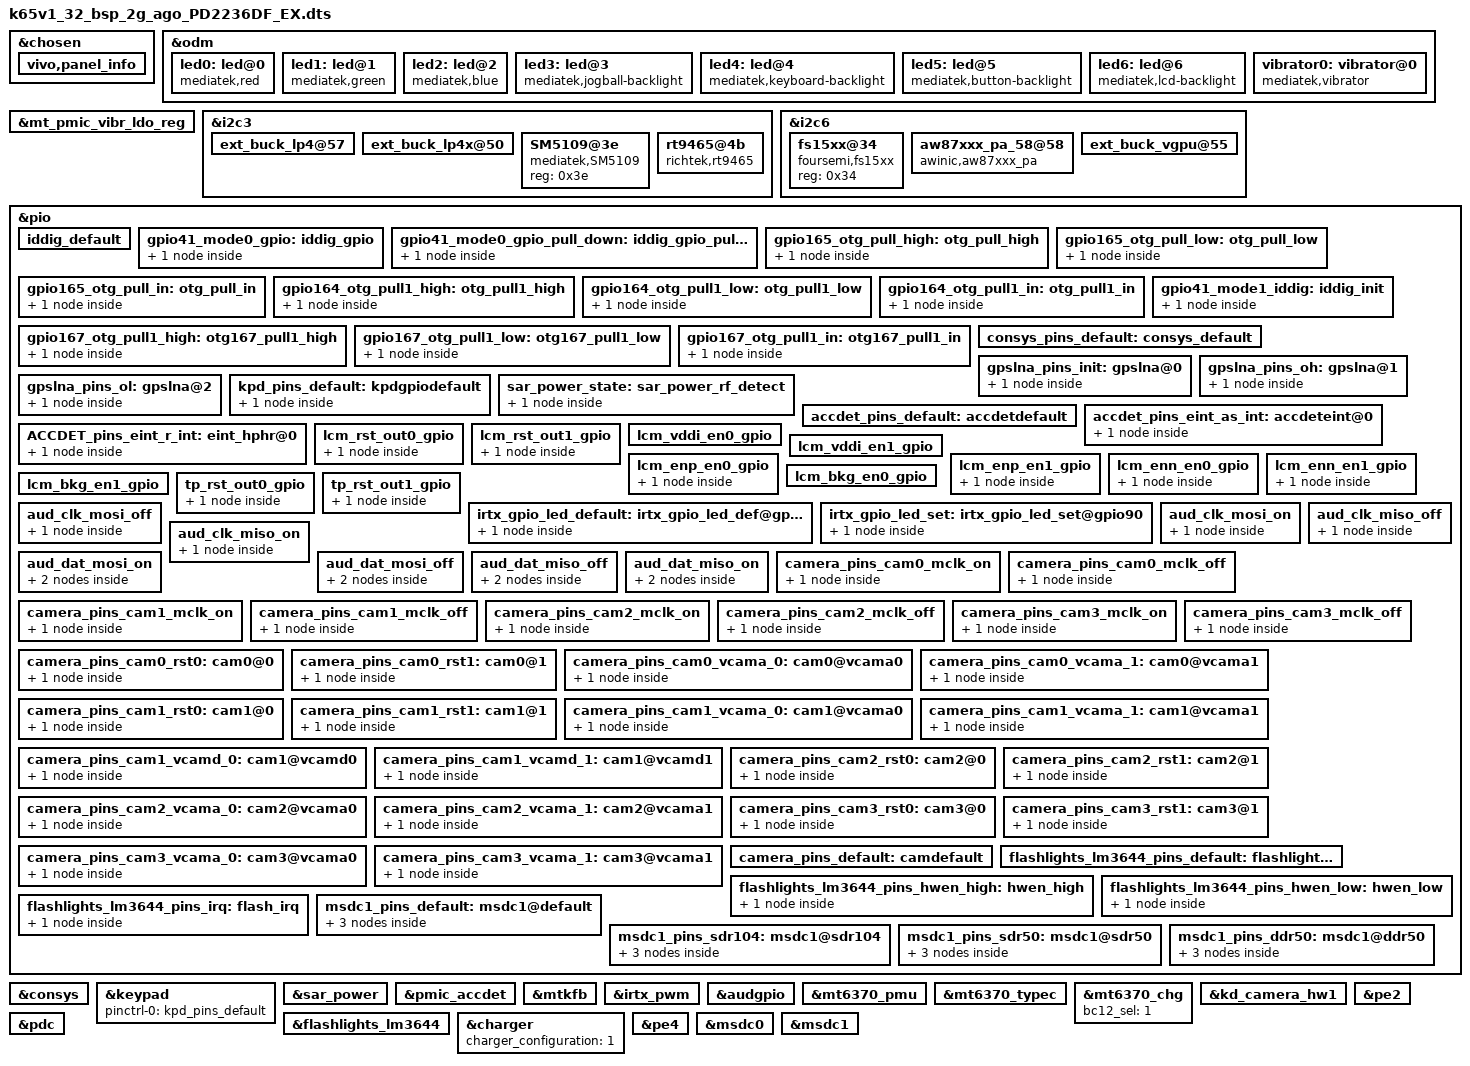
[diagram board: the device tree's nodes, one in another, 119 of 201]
// SPDX-License-Identifier: GPL-2.0+
/*
 * Copyright (c) 2019 MediaTek Inc.
 *
 */

#include <dt-bindings/interrupt-controller/arm-gic.h>
#include <dt-bindings/interrupt-controller/irq.h>
#include <dt-bindings/pinctrl/mt6765-pinfunc.h>
#include <dt-bindings/clock/mt6765-clk.h>
#include <dt-bindings/mmc/mt6765-msdc.h>

/dts-v1/;
/plugin/;

/* chosen */
&chosen {

	/* fpga may has no lk, we need to specify display info here */
	/* fb buffer is reserved using this dts by memory node above */
	atag,videolfb-fb_base_h = <0x0>;
	atag,videolfb-fb_base_l = <0x5e605000>;
	atag,videolfb-islcmfound = <1>;
	/* because no lk, so lcm is not inited */
	atag,videolfb-islcm_inited = <0>;
	atag,videolfb-fps= <6000>;
	atag,videolfb-vramSize= <0x017bb000>;
	atag,videolfb-lcmname= "pd2236_txd_jd9365t_hdplus_dsi_vdo";
	atag,videolfb-project-name= "PD2236DF_EX";
	/* vivo panel materiel info start */
	vivo,panel_info {
		/*
		 * No add new id until you have import driver for new panel ok!!!!!!
		 * vivo,panel-materiel-id-list = "materiel_id1", "lcm1_sf_id1 lcm1_sf_id2 lcm1_sf_id3...",
		 *				 "materiel_id2", "lcm2_sf_id1 lcm2_sf_id2 lcm2_sf_id3...",
		 *				 ...
		 *				 "materiel_idX", "lcmX_sf_id1 lcmX_sf_id2 lcmX_sf_id3...";
		 */

		vivo,panel-materiel-id-list = "1111111","0x90",		/*txd_jd9365t*/
									  "2222222","0xB1",		/*ski651_icnl9911c*/
									  "3333333","0x12";     /*tianma_ili9883c*/
	};

	/* vivo panel materiel info end */
};

&odm {
	led0:led@0 {
		compatible = "mediatek,red";
		led_mode = <0>;
		data = <1>;
		pwm_config = <0 0 0 0 0>;
	};
	led1:led@1 {
		compatible = "mediatek,green";
		led_mode = <0>;
		data = <1>;
		pwm_config = <0 0 0 0 0>;
	};
	led2:led@2 {
		compatible = "mediatek,blue";
		led_mode = <0>;
		data = <1>;
		pwm_config = <0 0 0 0 0>;
	};
	led3:led@3 {
		compatible = "mediatek,jogball-backlight";
		led_mode = <0>;
		data = <1>;
		pwm_config = <0 0 0 0 0>;
	};
	led4:led@4 {
		compatible = "mediatek,keyboard-backlight";
		led_mode = <0>;
		data = <1>;
		pwm_config = <0 0 0 0 0>;
	};
	led5:led@5 {
		compatible = "mediatek,button-backlight";
		led_mode = <0>;
		data = <1>;
		pwm_config = <0 0 0 0 0>;
	};
	led6:led@6 {
		compatible = "mediatek,lcd-backlight";
		led_mode = <4>;
		data = <1>;
		pwm_config = <0 0 0 0 0>;
	};
	vibrator0:vibrator@0 {
		compatible = "mediatek,vibrator";
		vib_timer = <25>;
		vib_limit = <9>;
		vib_vol= <9>;
	};
};

&mt_pmic_vibr_ldo_reg {
	regulator-min-microvolt = <3000000>;
	regulator-max-microvolt = <3000000>;
};

&i2c3 {
	ext_buck_lp4@57 {
		regulator-name ="ext_buck_vdd2";
		regulator-min-microvolt = <300000>;
		regulator-max-microvolt = <1300000>;
		vsel_pin = <0>;
	};

	ext_buck_lp4x@50 {
		regulator-name ="ext_buck_vddq";
		regulator-min-microvolt = <300000>;
		regulator-max-microvolt = <1300000>;
		vsel_pin = <1>;
	};

	SM5109@3e {
		compatible = "mediatek,SM5109";
		reg = <0x3e>;
		status = "okay";
	};
};

&i2c6 {
	/* AWINIC FS1599 Smart K PA */
	fs15xx@34 {
		compatible = "foursemi,fs15xx";
		reg = <0x34>;
		status = "okay";
	};
	/* AWINIC FS1599 Smart K PA End */

	/* AWINIC AW87XXX Smart K PA */
	aw87xxx_pa_58@58 {
		compatible = "awinic,aw87xxx_pa";
		reg = <0x58>;
		//reset-gpio = <&pio 173 0>;
		dev_index = < 0 >;
		status = "okay";
	};
	/* AWINIC AW87XXX Smart K PA End */

	ext_buck_vgpu@55 {
		regulator-name ="ext_buck_vgpu";
		regulator-min-microvolt = <300000>;
		regulator-max-microvolt = <1300000>;
		vsel_pin = <2>;
	};
};

/*HQ charge add otg start*/
&pio {
	iddig_default: iddig_default {
	};

	gpio41_mode0_gpio: iddig_gpio {
		pins_cmd_dat {
			pinmux = <PINMUX_GPIO41__FUNC_GPIO41>;
			input-enable;
			slew-rate = <0>;
			bias-pull-up = <01>;
			bias-disable;
		};
	};

	gpio41_mode0_gpio_pull_down: iddig_gpio_pull_down {
		pins_cmd_dat {
			pinmux = <PINMUX_GPIO41__FUNC_GPIO41>;
			input-enable;
			slew-rate = <0>;
			/*bias-pull-up = <00>;*/
			bias-pull-down;
		};
	};

	gpio165_otg_pull_high: otg_pull_high {
		pins_cmd_dat {
			pinmux = <PINMUX_GPIO110__FUNC_GPIO110>;
			slew-rate = <1>;
			bias-pull-up = <1>;
			output-high;
		};
	};
	gpio165_otg_pull_low: otg_pull_low {
		pins_cmd_dat {
			pinmux = <PINMUX_GPIO110__FUNC_GPIO110>;
			slew-rate = <1>;
			output-low;
		};
	};
	gpio165_otg_pull_in: otg_pull_in {
		pins_cmd_dat {
			pinmux = <PINMUX_GPIO110__FUNC_GPIO110>;
			input-enable;
			slew-rate = <0>;
			/*bias-pull-up = <00>;*/
			bias-disable;
		};
	};

	gpio164_otg_pull1_high: otg_pull1_high {
		pins_cmd_dat {
			pinmux = <PINMUX_GPIO164__FUNC_GPIO164>;
			slew-rate = <1>;
			bias-pull-up = <1>;
			output-high;
		};
	};
	gpio164_otg_pull1_low: otg_pull1_low {
		pins_cmd_dat {
			pinmux = <PINMUX_GPIO164__FUNC_GPIO164>;
			slew-rate = <1>;
			output-low;
		};
	};
	gpio164_otg_pull1_in: otg_pull1_in {
		pins_cmd_dat {
			pinmux = <PINMUX_GPIO164__FUNC_GPIO164>;
			input-enable;
			slew-rate = <0>;
			/*bias-pull-up = <00>;*/
			bias-disable;
		};
	};

	gpio41_mode1_iddig: iddig_init {
		pins_cmd_dat {
			pinmux = <PINMUX_GPIO41__FUNC_IDDIG>;
			input-enable;
			slew-rate = <0>;
			bias-pull-up = <01>;
			bias-disable;
		};
	};

	gpio167_otg_pull1_high: otg167_pull1_high {
		pins_cmd_dat {
			pinmux = <PINMUX_GPIO167__FUNC_GPIO167>;
			slew-rate = <1>;
			bias-pull-up = <1>;
			output-high;
		};
	};
	gpio167_otg_pull1_low: otg167_pull1_low {
		pins_cmd_dat {
			pinmux = <PINMUX_GPIO167__FUNC_GPIO167>;
			slew-rate = <1>;
			output-low;
		};
	};
	gpio167_otg_pull1_in: otg167_pull1_in {
		pins_cmd_dat {
			pinmux = <PINMUX_GPIO167__FUNC_GPIO167>;
			input-enable;
			slew-rate = <0>;
			/*bias-pull-up = <00>;*/
			bias-disable;
		};
	};
};
/*HQ charge add otg end*/

/* CONSYS GPIO standardization */
&pio {
	consys_pins_default: consys_default {
	};
	gpslna_pins_init: gpslna@0 {
		pins_cmd_dat {
			pinmux = <PINMUX_GPIO91__FUNC_GPIO91>;
			slew-rate = <0>;
			bias-disable;
			output-low;
		};
	};
	gpslna_pins_oh: gpslna@1 {
		pins_cmd_dat {
			pinmux = <PINMUX_GPIO91__FUNC_GPIO91>;
			slew-rate = <1>;
			output-high;
		};
	};
	gpslna_pins_ol: gpslna@2 {
		pins_cmd_dat {
			pinmux = <PINMUX_GPIO91__FUNC_GPIO91>;
			slew-rate = <1>;
			output-low;
		};
	};
};
&consys {
	pinctrl-names = "default", "gps_lna_state_init",
		"gps_lna_state_oh", "gps_lna_state_ol";
	pinctrl-0 = <&consys_pins_default>;
	pinctrl-1 = <&gpslna_pins_init>;
	pinctrl-2 = <&gpslna_pins_oh>;
	pinctrl-3 = <&gpslna_pins_ol>;
	status = "okay";
};
/* CONSYS end */

&keypad {
	pinctrl-names = "default";
	pinctrl-0 = <&kpd_pins_default>;
};

&pio {
	kpd_pins_default: kpdgpiodefault {
		pins_cmd_dat {
			pinmux = <PINMUX_GPIO93__FUNC_KPCOL0>;
			bias-pull-up = <MTK_PUPD_SET_R1R0_10>;
			output-low;
			input-schmitt-enable;
		};
	};
};

/* ADD by vsensor team for SAR Power */
&pio {
	sar_power_state: sar_power_rf_detect {
		pins_cmd0_dat {
			pinmux = <PINMUX_GPIO54__FUNC_GPIO54>;
			slew-rate = <0>;
			bias-disable;
		};
	};
};

&sar_power {
	status="okay";
	pinctrl-names = "default";
	pinctrl-0 = <&sar_power_state>;
	sar-power-rf-detect,gpios= <&pio 54 0x0>;
};
/* ADD by vsensor team for SAR Power */

/* accdet start */
&pmic_accdet {
	accdet-mic-vol = <6>;
	headset-mode-setting = <0x500 0x500 1 0x1f0 0x800 0x800 0x2000 0x44>;
	accdet-plugout-debounce = <16>;
	accdet-mic-mode = <1>;
	headset-eint-level-pol = <8>;
	headset-three-key-threshold = <0 80 190 390>;
	headset-three-key-threshold-CDD = <0 121 192 600>;
	headset-four-key-threshold = <0 53 90 190 390>;
	pinctrl-names = "default", "state_eint_as_int","state_eint_r_as_int";
	pinctrl-0 = <&accdet_pins_default>;
	pinctrl-1 = <&accdet_pins_eint_as_int>;
	pinctrl-2 = <&ACCDET_pins_eint_r_int>;
	status = "okay";
};
&pio {
	accdet_pins_default: accdetdefault {
	};
	accdet_pins_eint_as_int: accdeteint@0 {
		pins_cmd_dat {
			pinmux = <PINMUX_GPIO4__FUNC_GPIO4>;
			slew-rate = <0>;
			bias-disable;
		};
	};
	ACCDET_pins_eint_r_int:eint_hphr@0{
			pins_cmd_dat {
				pinmux = <PINMUX_GPIO3__FUNC_GPIO3>;
				slew-rate = <0>;
				bias-disable;
			};
	};
};
/* accdet end */

/* FINGERPRINT start */
/*&spi0 {
	#address-cells = <1>;
	#size-cells = <0>;
	fingerprint@0 {
		compatible = "goodix,goodix-fp";
		reg = <0>;
		spi-max-frequency = <8000000>;
		netlink-event = <30>;
		status = "okay";
	};
};*/

/*&goodix_fp {
	pinctrl-names = "default", "reset_high", "reset_low";
	pinctrl-0 = <&fingerprint_default>;
	pinctrl-1 = <&fingerprint_reset_high>;
	pinctrl-2 = <&fingerprint_reset_low>;
	status = "okay";
};*/

/*&pio {
	fingerprint_default: state_default {
	};
	fingerprint_reset_high: state_reset_high {
		pins_cmd_dat {
			pinmux = <PINMUX_GPIO172__FUNC_GPIO172>;
			slew-rate = <1>;
			output-high;
		};
	};
	fingerprint_reset_low: state_reset_low {
		pins_cmd_dat {
			pinmux = <PINMUX_GPIO172__FUNC_GPIO172>;
			slew-rate = <1>;
			output-low;
		};
	};
};*/
/* FINGERPRINT end */


&i2c6 {
	#address-cells = <1>;
	#size-cells = <0>;
	clock-frequency = <400000>;
	mediatek,use-open-drain;
	/*lm3697_i2c@36 {
		compatible = "lm3697_i2c";
		reg = <0x36>;
		status = "okay";
	};*/
};

/* add for lcm gpio config start  */
&mtkfb {
	pinctrl-names = "lcm_rst_out0_gpio",
					"lcm_rst_out1_gpio",
					"lcm_vddi_en0_gpio",
					"lcm_vddi_en1_gpio",
					"lcm_enp_en0_gpio",
					"lcm_enp_en1_gpio",
					"lcm_enn_en0_gpio",
					"lcm_enn_en1_gpio",
					"lcm_bkg_en0_gpio",
					"lcm_bkg_en1_gpio",
					"tp_rst_out0_gpio",
					"tp_rst_out1_gpio";

	pinctrl-0 = <&lcm_rst_out0_gpio>;
	pinctrl-1 = <&lcm_rst_out1_gpio>;

	pinctrl-2 = <&lcm_vddi_en0_gpio>;
	pinctrl-3 = <&lcm_vddi_en1_gpio>;

	pinctrl-4 = <&lcm_enp_en0_gpio>;
	pinctrl-5 = <&lcm_enp_en1_gpio>;

	pinctrl-6 = <&lcm_enn_en0_gpio>;
	pinctrl-7 = <&lcm_enn_en1_gpio>;

	pinctrl-8 = <&lcm_bkg_en0_gpio>;
	pinctrl-9 = <&lcm_bkg_en1_gpio>;

	pinctrl-10 = <&tp_rst_out0_gpio>;
	pinctrl-11 = <&tp_rst_out1_gpio>;

	status = "okay";
};
&pio {
	lcm_rst_out0_gpio: lcm_rst_out0_gpio {
		pins_cmd_dat {
			pinmux = <PINMUX_GPIO45__FUNC_GPIO45>;
			slew-rate = <1>;
			output-low;
		};
	};
	lcm_rst_out1_gpio: lcm_rst_out1_gpio {
		pins_cmd_dat {
			pinmux = <PINMUX_GPIO45__FUNC_GPIO45>;
			slew-rate = <1>;
			output-high;
		};
	};
	lcm_vddi_en0_gpio: lcm_vddi_en0_gpio {
	};
	lcm_vddi_en1_gpio: lcm_vddi_en1_gpio {
	};

	lcm_enp_en0_gpio: lcm_enp_en0_gpio {
		pins_cmd_dat {
			pinmux = <PINMUX_GPIO166__FUNC_GPIO166>;
			slew-rate = <1>;
			output-low;
		};
	};
	lcm_enp_en1_gpio: lcm_enp_en1_gpio {
		pins_cmd_dat {
			pinmux = <PINMUX_GPIO166__FUNC_GPIO166>;
			slew-rate = <1>;
			output-high;
		};
	};

	lcm_enn_en0_gpio: lcm_enn_en0_gpio {
		pins_cmd_dat {
			pinmux = <PINMUX_GPIO165__FUNC_GPIO165>;
			slew-rate = <1>;
			output-low;
		};
	};
	lcm_enn_en1_gpio: lcm_enn_en1_gpio {
		pins_cmd_dat {
			pinmux = <PINMUX_GPIO165__FUNC_GPIO165>;
			slew-rate = <1>;
			output-high;
		};
	};

	lcm_bkg_en0_gpio: lcm_bkg_en0_gpio {
	};
	lcm_bkg_en1_gpio: lcm_bkg_en1_gpio {
	};

	tp_rst_out0_gpio: tp_rst_out0_gpio {
		pins_cmd_dat {
			pinmux = <PINMUX_GPIO178__FUNC_GPIO178>;
			slew-rate = <1>;
			output-low;
		};
	};
	tp_rst_out1_gpio: tp_rst_out1_gpio {
		pins_cmd_dat {
			pinmux = <PINMUX_GPIO178__FUNC_GPIO178>;
			slew-rate = <1>;
			output-high;
		};
	};
};
/* add for lcm gpio config end  */

/* IRTX GPIO start */
&irtx_pwm {
	pinctrl-names = "irtx_gpio_led_default", "irtx_gpio_led_set";
	pinctrl-0 = <&irtx_gpio_led_default>;
	pinctrl-1 = <&irtx_gpio_led_set>;
	status = "okay";
};
&pio {
	irtx_gpio_led_default:irtx_gpio_led_def@gpio90 {
		pins_cmd_dat {
			pinmux = <PINMUX_GPIO90__FUNC_GPIO90>;
			slew-rate = <1>;
			bias-disable;
			output-low;
			input-schmitt-enable = <0>;
		};
	};

	irtx_gpio_led_set:irtx_gpio_led_set@gpio90 {
		pins_cmd_dat {
			pinmux = <PINMUX_GPIO90__FUNC_PWM0>;
			slew-rate = <1>;
			output-high;
		};
	};
};
/* IRTX GPIO Settings -End */

/* AUDIO GPIO standardization */
&audgpio {
	pinctrl-names = "aud_clk_mosi_off",
			"aud_clk_mosi_on",
			"aud_clk_miso_off",
			"aud_clk_miso_on",
			"aud_dat_mosi_off",
			"aud_dat_mosi_on",
			"aud_dat_miso_off",
			"aud_dat_miso_on",
			"aud_smartpa_off",
			"aud_smartpa_on";
	pinctrl-0 = <&aud_clk_mosi_off>;
	pinctrl-1 = <&aud_clk_mosi_on>;
	pinctrl-2 = <&aud_clk_miso_off>;
	pinctrl-3 = <&aud_clk_miso_on>;
	pinctrl-4 = <&aud_dat_mosi_off>;
	pinctrl-5 = <&aud_dat_mosi_on>;
	pinctrl-6 = <&aud_dat_miso_off>;
	pinctrl-7 = <&aud_dat_miso_on>;
	//pinctrl-8 = <&aud_pins_smartpa_off>;
	//pinctrl-9 = <&aud_pins_smartpa_on>;
	status = "okay";
};

&pio {
	aud_clk_mosi_off: aud_clk_mosi_off {
		pins_cmd0_dat {
			pinmux = <PINMUX_GPIO136__FUNC_GPIO136>;
		};
	};

	aud_clk_mosi_on: aud_clk_mosi_on {
		pins_cmd0_dat {
			pinmux = <PINMUX_GPIO136__FUNC_AUD_CLK_MOSI>;
		};
	};

	aud_clk_miso_off: aud_clk_miso_off {
		pins_cmd0_dat {
			pinmux = <PINMUX_GPIO140__FUNC_GPIO140>;
		};
	};

	aud_clk_miso_on: aud_clk_miso_on {
		pins_cmd0_dat {
			pinmux = <PINMUX_GPIO140__FUNC_AUD_CLK_MISO>;
		};
	};

	aud_dat_mosi_off: aud_dat_mosi_off {
		pins_cmd1_dat {
			pinmux = <PINMUX_GPIO138__FUNC_GPIO138>;
			input-enable;
			slew-rate = <0>;
			bias-disable;
		};
		pins_cmd2_dat {
			pinmux = <PINMUX_GPIO139__FUNC_GPIO139>;
			input-enable;
			slew-rate = <0>;
			bias-disable;
		};
	};

	aud_dat_mosi_on: aud_dat_mosi_on {
		pins_cmd1_dat {
			pinmux = <PINMUX_GPIO138__FUNC_AUD_DAT_MOSI0>;
		};
		pins_cmd2_dat {
			pinmux = <PINMUX_GPIO139__FUNC_AUD_DAT_MOSI1>;
		};
	};

	aud_dat_miso_off: aud_dat_miso_off {
		pins_cmd1_dat {
			pinmux = <PINMUX_GPIO142__FUNC_GPIO142>;
			input-enable;
			slew-rate = <0>;
			bias-disable;
		};
		pins_cmd2_dat {
			pinmux = <PINMUX_GPIO143__FUNC_GPIO143>;
			input-enable;
			slew-rate = <0>;
			bias-disable;
		};
	};

	aud_dat_miso_on: aud_dat_miso_on {
		pins_cmd1_dat {
			pinmux = <PINMUX_GPIO142__FUNC_AUD_DAT_MISO0>;
		};
		pins_cmd2_dat {
			pinmux = <PINMUX_GPIO143__FUNC_AUD_DAT_MISO1>;
		};
	};
/*
	aud_pins_smartpa_off: aud_pins_smartpa_off {
		pins_cmd0_dat {
			pinmux = <PINMUX_GPIO17__FUNC_GPIO17>;
		};
		pins_cmd1_dat {
			pinmux = <PINMUX_GPIO18__FUNC_GPIO18>;
		};
		pins_cmd2_dat {
			pinmux = <PINMUX_GPIO19__FUNC_GPIO19>;
		};
		pins_cmd3_dat {
			pinmux = <PINMUX_GPIO20__FUNC_GPIO20>;
		};
	};

	aud_pins_smartpa_on: aud_pins_smartpa_on {
		pins_cmd0_dat {
			pinmux = <PINMUX_GPIO17__FUNC_I2S0_DI>;
		};
		pins_cmd1_dat {
			pinmux = <PINMUX_GPIO18__FUNC_I2S3_BCK>;
		};
		pins_cmd2_dat {
			pinmux = <PINMUX_GPIO19__FUNC_I2S3_LRCK>;
		};
		pins_cmd3_dat {
			pinmux = <PINMUX_GPIO20__FUNC_I2S3_DO>;
		};
	};
*/
};
/* AUDIO end */

&mt6370_pmu {
	mt6370,intr_gpio_num = <11>; /* direct defined GPIO num */
	mt6370,intr_gpio = <&pio 11 0x0>;
};

&mt6370_typec {
	mt6370pd,intr_gpio_num = <41>; /* direct defined GPIO num */
	mt6370pd,intr_gpio = <&pio 41 0x0>;
};

&mt6370_chg {
	bc12_sel = <1>;
};

&pio {
	camera_pins_cam0_mclk_on: camera_pins_cam0_mclk_on {
		pins_cmd_dat {
			pinmux = <PINMUX_GPIO99__FUNC_CMMCLK0>;
		};
	};
	camera_pins_cam0_mclk_off: camera_pins_cam0_mclk_off {
		pins_cmd_dat {
			pinmux = <PINMUX_GPIO99__FUNC_GPIO99>;
		};
	};
	camera_pins_cam1_mclk_on: camera_pins_cam1_mclk_on {
		pins_cmd_dat {
			pinmux = <PINMUX_GPIO100__FUNC_CMMCLK1>;
		};
	};
	camera_pins_cam1_mclk_off: camera_pins_cam1_mclk_off {
		pins_cmd_dat {
			pinmux = <PINMUX_GPIO100__FUNC_GPIO100>;
		};
	};
	camera_pins_cam2_mclk_on: camera_pins_cam2_mclk_on {
		pins_cmd_dat {
			pinmux = <PINMUX_GPIO108__FUNC_CMMCLK2>;
		};
	};
	camera_pins_cam2_mclk_off: camera_pins_cam2_mclk_off {
		pins_cmd_dat {
			pinmux = <PINMUX_GPIO108__FUNC_GPIO108>;
		};
	};
	camera_pins_cam3_mclk_on: camera_pins_cam3_mclk_on {
		pins_cmd_dat {
			pinmux = <PINMUX_GPIO100__FUNC_CMMCLK1>;
		};
	};
	camera_pins_cam3_mclk_off: camera_pins_cam3_mclk_off {
		pins_cmd_dat {
			pinmux = <PINMUX_GPIO100__FUNC_GPIO100>;
		};
	};
/* cam 0 main start*/
	camera_pins_cam0_rst0: cam0@0 {
		pins_cmd_dat {
			pinmux = <PINMUX_GPIO101__FUNC_GPIO101>;
			slew-rate = <1>;
			output-low;
		};
	};
	camera_pins_cam0_rst1: cam0@1 {
		pins_cmd_dat {
			pinmux = <PINMUX_GPIO101__FUNC_GPIO101>;
			slew-rate = <1>;
			output-high;
		};
	};

	camera_pins_cam0_vcama_0: cam0@vcama0 {
		pins_cmd_dat {
			pinmux = <PINMUX_GPIO156__FUNC_GPIO156>;
			slew-rate = <1>;
			output-low;
		};
	};
	camera_pins_cam0_vcama_1: cam0@vcama1 {
		pins_cmd_dat {
			pinmux = <PINMUX_GPIO156__FUNC_GPIO156>;
			slew-rate = <1>;
			output-high;
		};
	};
/* cam 0 main end*/

/* cam 1 sub start*/

	camera_pins_cam1_rst0: cam1@0 {
		pins_cmd_dat {
			pinmux = <PINMUX_GPIO102__FUNC_GPIO102>;
			slew-rate = <1>;
			output-low;
		};
	};
	camera_pins_cam1_rst1: cam1@1 {
		pins_cmd_dat {
			pinmux = <PINMUX_GPIO102__FUNC_GPIO102>;
			slew-rate = <1>;
			output-high;
		};
	};
	camera_pins_cam1_vcama_0: cam1@vcama0 {
		pins_cmd_dat {
			pinmux = <PINMUX_GPIO156__FUNC_GPIO156>;
			slew-rate = <1>;
			output-low;
		};
	};
	camera_pins_cam1_vcama_1: cam1@vcama1 {
		pins_cmd_dat {
			pinmux = <PINMUX_GPIO156__FUNC_GPIO156>;
			slew-rate = <1>;
			output-high;
		};
	};
	camera_pins_cam1_vcamd_0: cam1@vcamd0 {
		pins_cmd_dat {
			pinmux = <PINMUX_GPIO98__FUNC_GPIO98>;
			slew-rate = <1>;
			output-low;
		};
	};
	camera_pins_cam1_vcamd_1: cam1@vcamd1 {
		pins_cmd_dat {
			pinmux = <PINMUX_GPIO98__FUNC_GPIO98>;
			slew-rate = <1>;
			output-high;
		};
	};

/* cam 1 sub end*/

/* cam 2 main2 start*/

	camera_pins_cam2_rst0: cam2@0 {
		pins_cmd_dat {
			pinmux = <PINMUX_GPIO109__FUNC_GPIO109>;
			slew-rate = <1>;
			output-low;
		};
	};
	camera_pins_cam2_rst1: cam2@1 {
		pins_cmd_dat {
			pinmux = <PINMUX_GPIO109__FUNC_GPIO109>;
			slew-rate = <1>;
			output-high;
		};

	};
	camera_pins_cam2_vcama_0: cam2@vcama0 {
		pins_cmd_dat {
			pinmux = <PINMUX_GPIO156__FUNC_GPIO156>;
			slew-rate = <1>;
			output-low;
		};
	};
	camera_pins_cam2_vcama_1: cam2@vcama1 {
		pins_cmd_dat {
			pinmux = <PINMUX_GPIO156__FUNC_GPIO156>;
			slew-rate = <1>;
			output-high;
		};
	};

/* cam 2 main2 end*/

/* cam 3 main3 start*/

	camera_pins_cam3_rst0: cam3@0 {
		pins_cmd_dat {
			pinmux = <PINMUX_GPIO102__FUNC_GPIO102>;
			slew-rate = <1>;
			output-low;
		};
	};
	camera_pins_cam3_rst1: cam3@1 {
		pins_cmd_dat {
			pinmux = <PINMUX_GPIO102__FUNC_GPIO102>;
			slew-rate = <1>;
			output-high;
		};

	};
	camera_pins_cam3_vcama_0: cam3@vcama0 {
		pins_cmd_dat {
			pinmux = <PINMUX_GPIO97__FUNC_GPIO97>;
			slew-rate = <1>;
			output-low;
		};
	};
	camera_pins_cam3_vcama_1: cam3@vcama1 {
		pins_cmd_dat {
			pinmux = <PINMUX_GPIO97__FUNC_GPIO97>;
			slew-rate = <1>;
			output-high;
		};
	};

/* cam 3 main3 end*/

	camera_pins_default: camdefault {
	};

};

&kd_camera_hw1 {
	pinctrl-names = "default",
			"cam0_rst0",
			"cam0_rst1",
			"cam1_rst0",
			"cam1_rst1",
			//"cam2_rst0",
			//"cam2_rst1",
			//"cam3_rst0",
			//"cam3_rst1",
			"cam0_ldo_vcama_0","cam0_ldo_vcama_1",
			//"cam1_ldo_vcamd_0","cam1_ldo_vcamd_1",
			"cam1_ldo_vcama_0","cam1_ldo_vcama_1",
			//"cam2_ldo_vcama_0","cam2_ldo_vcama_1",
			//"cam3_ldo_vcama_0","cam3_ldo_vcama_1",
			"cam0_mclk_on",
			"cam0_mclk_off",
			"cam1_mclk_on",
			"cam1_mclk_off";
			//"cam2_mclk_on",
			//"cam2_mclk_off",
			//"cam3_mclk_on",
			//"cam3_mclk_off";
	pinctrl-0 = <&camera_pins_default>;
	pinctrl-1 = <&camera_pins_cam0_rst0>;
	pinctrl-2 = <&camera_pins_cam0_rst1>;
	pinctrl-3 = <&camera_pins_cam1_rst0>;
	pinctrl-4 = <&camera_pins_cam1_rst1>;
	pinctrl-5 = <&camera_pins_cam0_vcama_0>;
	pinctrl-6 = <&camera_pins_cam0_vcama_1>;
	pinctrl-7 = <&camera_pins_cam1_vcama_0>;
	pinctrl-8 = <&camera_pins_cam1_vcama_1>;
	pinctrl-9 = <&camera_pins_cam0_mclk_on>;
	pinctrl-10 = <&camera_pins_cam0_mclk_off>;
	pinctrl-11 = <&camera_pins_cam1_mclk_on>;
	pinctrl-12 = <&camera_pins_cam1_mclk_off>;

	status = "okay";

};
/* FLASHLIGHT START*/
&pio {
	flashlights_lm3644_pins_default: flashlight_default {
	};

	flashlights_lm3644_pins_hwen_high: hwen_high {
		pins_cmd_dat {
			pinmux = <PINMUX_GPIO157__FUNC_GPIO157>;
			slew-rate = <1>;
			output-high;
		};
	};

	flashlights_lm3644_pins_hwen_low: hwen_low {
		pins_cmd_dat {
			pinmux = <PINMUX_GPIO157__FUNC_GPIO157>;
			slew-rate = <1>;
			output-low;
		};
	};

	flashlights_lm3644_pins_irq: flash_irq {
		pins_cmd_dat {
			pinmux = <PINMUX_GPIO107__FUNC_GPIO107>;
			slew-rate = <0>;
			bias-disable;
		};
	};


};

&flashlights_lm3644 {
	pinctrl-names = "default", "hwen_high", "hwen_low", "flash_irq";
	pinctrl-0 = <&flashlights_lm3644_pins_default>;
	pinctrl-1 = <&flashlights_lm3644_pins_hwen_high>;
	pinctrl-2 = <&flashlights_lm3644_pins_hwen_low>;
	pinctrl-3 = <&flashlights_lm3644_pins_irq>;
	status = "okay";
};

&i2c3 {
	rt9465@4b {
		compatible = "richtek,rt9465";
		reg = <0x4b>;
		status = "okay";
		rt,en_gpio_num = <176>;
		rt,en_gpio = <&pio 176 0x0>;
		rt,intr_gpio_num = <23>; /* direct defined GPIO num */
		rt,intr_gpio = <&pio 23 0x0>;
		interrupt-names = "wdtmri";
		charger_name = "secondary_chg";
		ichg = <1500000>; /* uA */
		mivr = <4500000>; /* uV */
		cv = <4550000>; /* uV */
		ieoc = <700000>; /* uA */
		safety_timer = <12>; /* hour */
		en_st; /* safety timer */
		/* en_te; */
		en_wdt;
	};
};

&charger {
	charger_configuration= <1>;
};

&pe2 {
	dcs_chg1_charger_current = <2000000>;
	dcs_chg2_charger_current = <2000000>;
};

&pdc {
	pd_vbus_upper_bound = <12000000>;
	dcs_chg1_charger_current = <2000000>;
	dcs_chg2_charger_current = <2000000>;
};

&pe4 {
	dcs_chg1_charger_current = <2000000>;
	dcs_chg2_charger_current = <2000000>;
};

/*BSP memory add for mmc driver strength --start*/
&msdc0 {
	index = /bits/ 8 <0>;
	clk_src = /bits/ 8 <MSDC0_CLKSRC_400MHZ>;
	bus-width = <8>;
	max-frequency = <200000000>;
	cap-mmc-highspeed;
	mmc-ddr-1_8v;
	mmc-hs200-1_8v;
	mmc-hs400-1_8v;
	no-sd;
	no-sdio;
	non-removable;
	pinctl = <&msdc0_pins_default>;
	pinctl_hs400 = <&msdc0_pins_hs400>;
	pinctl_hs200 = <&msdc0_pins_hs200>;
	register_setting = <&msdc0_register_setting_default>;
	host_function = /bits/ 8 <MSDC_EMMC>;
	bootable;
	status = "okay";

#ifndef CONFIG_FPGA_EARLY_PORTING
	vmmc-supply = <&mt_pmic_vemc_ldo_reg>;
	clocks = <&infracfg_ao CLK_IFR_MSDC0_SRC>,
		<&infracfg_ao CLK_IFR_MSDC0>,
		<&infracfg_ao CLK_IFR_FAES_FDE>;
	clock-names = "msdc0-clock", "msdc0-hclock", "msdc0-aes-clock";
#endif
};

&msdc1 {
	fast_power_off;
	PD2213F_EX;
	pinctl = <&msdc1_pins_default>;
	pinctl_sdr104 = <&msdc1_pins_sdr104>;
	pinctl_sdr50 = <&msdc1_pins_sdr50>;
	pinctl_ddr50 = <&msdc1_pins_ddr50>;
};

&pio {
	msdc1_pins_default: msdc1@default {
		pins_cmd {
			drive-strength = /bits/ 8 <3>;
		};
		pins_dat {
			drive-strength = /bits/ 8 <3>;
		};
		pins_clk {
			drive-strength = /bits/ 8 <3>;
		};
	};

	msdc1_pins_sdr104: msdc1@sdr104 {
		pins_cmd {
			drive-strength = /bits/ 8 <3>;
		};
		pins_dat {
			drive-strength = /bits/ 8 <3>;
		};
		pins_clk {
			drive-strength = /bits/ 8 <3>;
		};
	};

	msdc1_pins_sdr50: msdc1@sdr50 {
		pins_cmd {
			drive-strength = /bits/ 8 <3>;
		};
		pins_dat {
			drive-strength = /bits/ 8 <3>;
		};
		pins_clk {
			drive-strength = /bits/ 8 <3>;
		};
	};

	msdc1_pins_ddr50: msdc1@ddr50 {
		pins_cmd {
			drive-strength = /bits/ 8 <3>;
		};
		pins_dat {
			drive-strength = /bits/ 8 <3>;
		};
		pins_clk {
			drive-strength = /bits/ 8 <3>;
		};
	};
};
/*BSP memory add for mmc driver strength --end*/

#include "cust_vivo_PD2236DF_EX.dtsi"
//#include "mediatek/cust_mt6765_camera.dtsi"
#include "vivo_tp_setting/mtk-vivo-tp-PD2236DF_EX.dtsi"
//#include "mediatek/fingerprint/mtk6762-vivo-fp-PD2213F_EX.dtsi"
/*End of this file, DO NOT ADD ANYTHING HERE*/
